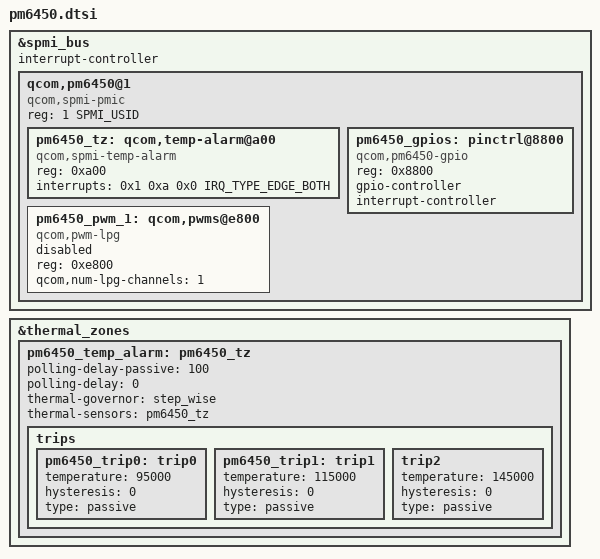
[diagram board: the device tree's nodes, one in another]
#include <dt-bindings/interrupt-controller/irq.h>
#include <dt-bindings/spmi/spmi.h>

&spmi_bus {
	#address-cells = <2>;
	#size-cells = <0>;
	interrupt-controller;
	#interrupt-cells = <4>;

	qcom,pm6450@1 {
		compatible = "qcom,spmi-pmic";
		reg = <1 SPMI_USID>;
		#address-cells = <1>;
		#size-cells = <0>;

		pm6450_tz: qcom,temp-alarm@a00 {
			compatible = "qcom,spmi-temp-alarm";
			reg = <0xa00>;
			interrupts = <0x1 0xa 0x0 IRQ_TYPE_EDGE_BOTH>;
			#thermal-sensor-cells = <0>;
		};

		pm6450_gpios: pinctrl@8800 {
			compatible = "qcom,pm6450-gpio";
			reg = <0x8800>;
			gpio-controller;
			#gpio-cells = <2>;
			interrupt-controller;
			#interrupt-cells = <2>;
		};

		pm6450_pwm_1: qcom,pwms@e800 {
			status = "disabled";
			compatible = "qcom,pwm-lpg";
			reg = <0xe800>;
			reg-names = "lpg-base";
			qcom,num-lpg-channels = <1>;
			#pwm-cells = <2>;
		};
	};
};

&thermal_zones {
	pm6450_temp_alarm: pm6450_tz {
		polling-delay-passive = <100>;
		polling-delay = <0>;
		thermal-governor = "step_wise";
		thermal-sensors = <&pm6450_tz>;

		trips {
			pm6450_trip0: trip0 {
				temperature = <95000>;
				hysteresis = <0>;
				type = "passive";
			};

			pm6450_trip1: trip1 {
				temperature = <115000>;
				hysteresis = <0>;
				type = "passive";
			};

			trip2 {
				temperature = <145000>;
				hysteresis = <0>;
				type = "passive";
			};
		};
	};
};
